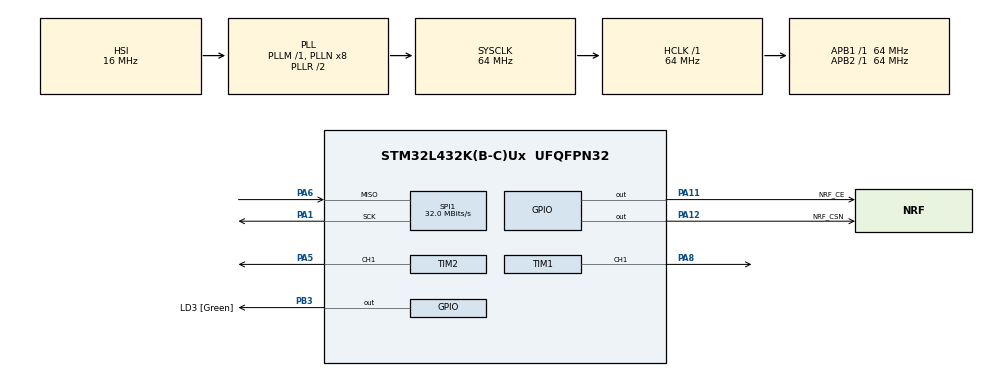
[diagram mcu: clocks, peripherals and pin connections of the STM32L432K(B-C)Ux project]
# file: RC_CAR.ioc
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FREERTOS.Tasks01=defaultTask,24,128,StartDefaultTask,Default,NULL,Dynamic,NULL,NULL
Mcu.Family=STM32L4
Mcu.Name=STM32L432K(B-C)Ux
Mcu.Package=UFQFPN32
NVIC.PriorityGroup=NVIC_PRIORITYGROUP_4
NVIC.TIM7_IRQn=true\:15\:0\:false\:false\:true\:false\:false\:true\:true
NVIC.TimeBase=TIM7_IRQn
NVIC.TimeBaseIP=TIM7
PA1.Mode=RX_Only_Simplex_Unidirect_Master
PA1.Signal=SPI1_SCK
PA11.GPIO_Label=NRF_CE
PA11.Signal=GPIO_Output
PA12.GPIO_Label=NRF_CSN
PA12.Signal=GPIO_Output
PA5.Signal=S_TIM2_CH1
PA6.Mode=RX_Only_Simplex_Unidirect_Master
PA6.Signal=SPI1_MISO
PA8.Signal=S_TIM1_CH1
PB3\ (JTDO-TRACESWO).GPIO_Label=LD3 [Green]
PB3\ (JTDO-TRACESWO).Signal=GPIO_Output
ProjectManager.HeapSize=0x200
ProjectManager.StackSize=0x400
ProjectManager.TargetToolchain=Makefile
RCC.ADCFreq_Value=64000000
RCC.AHBFreq_Value=64000000
RCC.APB1Freq_Value=64000000
RCC.APB1TimFreq_Value=64000000
RCC.APB2Freq_Value=64000000
RCC.APB2TimFreq_Value=64000000
RCC.CortexFreq_Value=64000000
RCC.HCLKFreq_Value=64000000
RCC.HSE_VALUE=8000000
RCC.HSI16_VALUE=16000000
RCC.HSI48_VALUE=48000000
RCC.HSI_VALUE=16000000
RCC.LSE_VALUE=32768
RCC.MSI_VALUE=4000000
RCC.PLLMUL=RCC_PLLMUL_4
RCC.PLLSourceVirtual=RCC_PLLSOURCE_HSI
RCC.SYSCLKFreq_VALUE=64000000
RCC.SYSCLKSource=RCC_SYSCLKSOURCE_PLLCLK
RCC.USBFreq_Value=64000000
RCC.VCOOutputFreq_Value=128000000
SH.S_TIM1_CH1.0=TIM1_CH1,PWM Generation1 CH1
SH.S_TIM2_CH1.0=TIM2_CH1,PWM Generation1 CH1
SPI1.BaudRatePrescaler=SPI_BAUDRATEPRESCALER_2
SPI1.CalculateBaudRate=32.0 MBits/s
SPI1.Direction=SPI_DIRECTION_2LINES_RXONLY
SPI1.Mode=SPI_MODE_MASTER
SPI1.VirtualType=VM_MASTER
TIM1.AutoReloadPreload=TIM_AUTORELOAD_PRELOAD_ENABLE
TIM1.Channel-PWM\ Generation1\ CH1=TIM_CHANNEL_1
TIM1.Period=3999
TIM1.Prescaler=319
TIM1.Pulse-PWM\ Generation1\ CH1=0
TIM2.AutoReloadPreload=TIM_AUTORELOAD_PRELOAD_ENABLE
TIM2.Channel-PWM\ Generation1\ CH1=TIM_CHANNEL_1
TIM2.Period=19999
TIM2.Prescaler=63
TIM2.Pulse-PWM\ Generation1\ CH1=1500
VP_FREERTOS_VS_CMSIS_V2.Mode=CMSIS_V2
VP_SYS_VS_tim7.Mode=TIM7
VP_TIM1_VS_ClockSourceINT.Mode=Internal
VP_TIM2_VS_ClockSourceINT.Mode=Internal
board=NUCLEO-L432KC

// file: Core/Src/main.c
/* USER CODE BEGIN Header */
/**
 ******************************************************************************
 * @file           : main.c
 * @brief          : Main program body
 ******************************************************************************
 * @attention
 *
 * Copyright (c) 2024 STMicroelectronics.
 * All rights reserved.
 *
 * This software is licensed under terms that can be found in the LICENSE file
 * in the root directory of this software component.
 * If no LICENSE file comes with this software, it is provided AS-IS.
 *
 ******************************************************************************
 */
/* USER CODE END Header */
#include "main.h"
#include "cmsis_os.h"

SPI_HandleTypeDef hspi1;

TIM_HandleTypeDef htim1;
TIM_HandleTypeDef htim2;

/* Definitions for defaultTask */
osThreadId_t defaultTaskHandle;
const osThreadAttr_t defaultTask_attributes = {
  .name = "defaultTask",
  .stack_size = 128 * 4,
  .priority = (osPriority_t) osPriorityNormal,
};

void SystemClock_Config(void);
static void MX_GPIO_Init(void);
static void MX_SPI1_Init(void);
static void MX_TIM1_Init(void);
static void MX_TIM2_Init(void);
void StartDefaultTask(void *argument);

int main(void)
{

  /* MCU Configuration--------------------------------------------------------*/

  /* Reset of all peripherals, Initializes the Flash interface and the Systick. */
  HAL_Init();

  /* Configure the system clock */
  SystemClock_Config();

  /* Initialize all configured peripherals */
  MX_GPIO_Init();
  MX_SPI1_Init();
  MX_TIM1_Init();
  MX_TIM2_Init();
  /* USER CODE BEGIN 2 */
  Car_Init();

  /* USER CODE END 2 */

  /* Init scheduler */
  osKernelInitialize();

  /* Create the thread(s) */
  /* creation of defaultTask */
  defaultTaskHandle = osThreadNew(StartDefaultTask, NULL, &defaultTask_attributes);

  /* Start scheduler */
  osKernelStart();

  /* We should never get here as control is now taken by the scheduler */

  /* Infinite loop */
  while (1)
  {

  }
}

void SystemClock_Config(void)
{
  RCC_OscInitTypeDef RCC_OscInitStruct = {0};
  RCC_ClkInitTypeDef RCC_ClkInitStruct = {0};

  /** Configure the main internal regulator output voltage
  */
  if (HAL_PWREx_ControlVoltageScaling(PWR_REGULATOR_VOLTAGE_SCALE1) != HAL_OK)
  {
    Error_Handler();
  }

  /** Initializes the RCC Oscillators according to the specified parameters
  * in the RCC_OscInitTypeDef structure.
  */
  RCC_OscInitStruct.OscillatorType = RCC_OSCILLATORTYPE_HSI;
  RCC_OscInitStruct.HSIState = RCC_HSI_ON;
  RCC_OscInitStruct.HSICalibrationValue = RCC_HSICALIBRATION_DEFAULT;
  RCC_OscInitStruct.PLL.PLLState = RCC_PLL_ON;
  RCC_OscInitStruct.PLL.PLLSource = RCC_PLLSOURCE_HSI;
  RCC_OscInitStruct.PLL.PLLM = 1;
  RCC_OscInitStruct.PLL.PLLN = 8;
  RCC_OscInitStruct.PLL.PLLP = RCC_PLLP_DIV7;
  RCC_OscInitStruct.PLL.PLLQ = RCC_PLLQ_DIV2;
  RCC_OscInitStruct.PLL.PLLR = RCC_PLLR_DIV2;
  if (HAL_RCC_OscConfig(&RCC_OscInitStruct) != HAL_OK)
  {
    Error_Handler();
  }

  /** Initializes the CPU, AHB and APB buses clocks
  */
  RCC_ClkInitStruct.ClockType = RCC_CLOCKTYPE_HCLK|RCC_CLOCKTYPE_SYSCLK
                              |RCC_CLOCKTYPE_PCLK1|RCC_CLOCKTYPE_PCLK2;
  RCC_ClkInitStruct.SYSCLKSource = RCC_SYSCLKSOURCE_PLLCLK;
  RCC_ClkInitStruct.AHBCLKDivider = RCC_SYSCLK_DIV1;
  RCC_ClkInitStruct.APB1CLKDivider = RCC_HCLK_DIV1;
  RCC_ClkInitStruct.APB2CLKDivider = RCC_HCLK_DIV1;

  if (HAL_RCC_ClockConfig(&RCC_ClkInitStruct, FLASH_LATENCY_3) != HAL_OK)
  {
    Error_Handler();
  }
}

static void MX_SPI1_Init(void)
{

  /* SPI1 parameter configuration*/
  hspi1.Instance = SPI1;
  hspi1.Init.Mode = SPI_MODE_MASTER;
  hspi1.Init.Direction = SPI_DIRECTION_2LINES_RXONLY;
  hspi1.Init.DataSize = SPI_DATASIZE_4BIT;
  hspi1.Init.CLKPolarity = SPI_POLARITY_LOW;
  hspi1.Init.CLKPhase = SPI_PHASE_1EDGE;
  hspi1.Init.NSS = SPI_NSS_SOFT;
  hspi1.Init.BaudRatePrescaler = SPI_BAUDRATEPRESCALER_2;
  hspi1.Init.FirstBit = SPI_FIRSTBIT_MSB;
  hspi1.Init.TIMode = SPI_TIMODE_DISABLE;
  hspi1.Init.CRCCalculation = SPI_CRCCALCULATION_DISABLE;
  hspi1.Init.CRCPolynomial = 7;
  hspi1.Init.CRCLength = SPI_CRC_LENGTH_DATASIZE;
  hspi1.Init.NSSPMode = SPI_NSS_PULSE_ENABLE;
  if (HAL_SPI_Init(&hspi1) != HAL_OK)
  {
    Error_Handler();
  }

}

static void MX_TIM1_Init(void)
{

  TIM_ClockConfigTypeDef sClockSourceConfig = {0};
  TIM_MasterConfigTypeDef sMasterConfig = {0};
  TIM_OC_InitTypeDef sConfigOC = {0};
  TIM_BreakDeadTimeConfigTypeDef sBreakDeadTimeConfig = {0};

  htim1.Instance = TIM1;
  htim1.Init.Prescaler = 319;
  htim1.Init.CounterMode = TIM_COUNTERMODE_UP;
  htim1.Init.Period = 3999;
  htim1.Init.ClockDivision = TIM_CLOCKDIVISION_DIV1;
  htim1.Init.RepetitionCounter = 0;
  htim1.Init.AutoReloadPreload = TIM_AUTORELOAD_PRELOAD_ENABLE;
  if (HAL_TIM_Base_Init(&htim1) != HAL_OK)
  {
    Error_Handler();
  }
  sClockSourceConfig.ClockSource = TIM_CLOCKSOURCE_INTERNAL;
  if (HAL_TIM_ConfigClockSource(&htim1, &sClockSourceConfig) != HAL_OK)
  {
    Error_Handler();
  }
  if (HAL_TIM_PWM_Init(&htim1) != HAL_OK)
  {
    Error_Handler();
  }
  sMasterConfig.MasterOutputTrigger = TIM_TRGO_RESET;
  sMasterConfig.MasterOutputTrigger2 = TIM_TRGO2_RESET;
  sMasterConfig.MasterSlaveMode = TIM_MASTERSLAVEMODE_DISABLE;
  if (HAL_TIMEx_MasterConfigSynchronization(&htim1, &sMasterConfig) != HAL_OK)
  {
    Error_Handler();
  }
  sConfigOC.OCMode = TIM_OCMODE_PWM1;
  sConfigOC.Pulse = 0;
  sConfigOC.OCPolarity = TIM_OCPOLARITY_HIGH;
  sConfigOC.OCNPolarity = TIM_OCNPOLARITY_HIGH;
  sConfigOC.OCFastMode = TIM_OCFAST_DISABLE;
  sConfigOC.OCIdleState = TIM_OCIDLESTATE_RESET;
  sConfigOC.OCNIdleState = TIM_OCNIDLESTATE_RESET;
  if (HAL_TIM_PWM_ConfigChannel(&htim1, &sConfigOC, TIM_CHANNEL_1) != HAL_OK)
  {
    Error_Handler();
  }
  sBreakDeadTimeConfig.OffStateRunMode = TIM_OSSR_DISABLE;
  sBreakDeadTimeConfig.OffStateIDLEMode = TIM_OSSI_DISABLE;
  sBreakDeadTimeConfig.LockLevel = TIM_LOCKLEVEL_OFF;
  sBreakDeadTimeConfig.DeadTime = 0;
  sBreakDeadTimeConfig.BreakState = TIM_BREAK_DISABLE;
  sBreakDeadTimeConfig.BreakPolarity = TIM_BREAKPOLARITY_HIGH;
  sBreakDeadTimeConfig.BreakFilter = 0;
  sBreakDeadTimeConfig.Break2State = TIM_BREAK2_DISABLE;
  sBreakDeadTimeConfig.Break2Polarity = TIM_BREAK2POLARITY_HIGH;
  sBreakDeadTimeConfig.Break2Filter = 0;
  sBreakDeadTimeConfig.AutomaticOutput = TIM_AUTOMATICOUTPUT_DISABLE;
  if (HAL_TIMEx_ConfigBreakDeadTime(&htim1, &sBreakDeadTimeConfig) != HAL_OK)
  {
    Error_Handler();
  }
  HAL_TIM_MspPostInit(&htim1);

}

static void MX_TIM2_Init(void)
{

  TIM_ClockConfigTypeDef sClockSourceConfig = {0};
  TIM_MasterConfigTypeDef sMasterConfig = {0};
  TIM_OC_InitTypeDef sConfigOC = {0};

  htim2.Instance = TIM2;
  htim2.Init.Prescaler = 63;
  htim2.Init.CounterMode = TIM_COUNTERMODE_UP;
  htim2.Init.Period = 19999;
  htim2.Init.ClockDivision = TIM_CLOCKDIVISION_DIV1;
  htim2.Init.AutoReloadPreload = TIM_AUTORELOAD_PRELOAD_ENABLE;
  if (HAL_TIM_Base_Init(&htim2) != HAL_OK)
  {
    Error_Handler();
  }
  sClockSourceConfig.ClockSource = TIM_CLOCKSOURCE_INTERNAL;
  if (HAL_TIM_ConfigClockSource(&htim2, &sClockSourceConfig) != HAL_OK)
  {
    Error_Handler();
  }
  if (HAL_TIM_PWM_Init(&htim2) != HAL_OK)
  {
    Error_Handler();
  }
  sMasterConfig.MasterOutputTrigger = TIM_TRGO_RESET;
  sMasterConfig.MasterSlaveMode = TIM_MASTERSLAVEMODE_DISABLE;
  if (HAL_TIMEx_MasterConfigSynchronization(&htim2, &sMasterConfig) != HAL_OK)
  {
    Error_Handler();
  }
  sConfigOC.OCMode = TIM_OCMODE_PWM1;
  sConfigOC.Pulse = 1500;
  sConfigOC.OCPolarity = TIM_OCPOLARITY_HIGH;
  sConfigOC.OCFastMode = TIM_OCFAST_DISABLE;
  if (HAL_TIM_PWM_ConfigChannel(&htim2, &sConfigOC, TIM_CHANNEL_1) != HAL_OK)
  {
    Error_Handler();
  }
  HAL_TIM_MspPostInit(&htim2);

}

static void MX_GPIO_Init(void)
{
  GPIO_InitTypeDef GPIO_InitStruct = {0};

  /* GPIO Ports Clock Enable */
  __HAL_RCC_GPIOA_CLK_ENABLE();
  __HAL_RCC_GPIOB_CLK_ENABLE();

  /*Configure GPIO pin Output Level */
  HAL_GPIO_WritePin(GPIOA, NRF_CE_Pin|NRF_CSN_Pin, GPIO_PIN_RESET);

  /*Configure GPIO pin Output Level */
  HAL_GPIO_WritePin(LD3_GPIO_Port, LD3_Pin, GPIO_PIN_RESET);

  /*Configure GPIO pins : NRF_CE_Pin NRF_CSN_Pin */
  GPIO_InitStruct.Pin = NRF_CE_Pin|NRF_CSN_Pin;
  GPIO_InitStruct.Mode = GPIO_MODE_OUTPUT_PP;
  GPIO_InitStruct.Pull = GPIO_NOPULL;
  GPIO_InitStruct.Speed = GPIO_SPEED_FREQ_LOW;
  HAL_GPIO_Init(GPIOA, &GPIO_InitStruct);

  /*Configure GPIO pin : LD3_Pin */
  GPIO_InitStruct.Pin = LD3_Pin;
  GPIO_InitStruct.Mode = GPIO_MODE_OUTPUT_PP;
  GPIO_InitStruct.Pull = GPIO_NOPULL;
  GPIO_InitStruct.Speed = GPIO_SPEED_FREQ_LOW;
  HAL_GPIO_Init(LD3_GPIO_Port, &GPIO_InitStruct);

}

void StartDefaultTask(void *argument)
{
  for (;;)
  {
    osDelay(1);
  }
}

void HAL_TIM_PeriodElapsedCallback(TIM_HandleTypeDef *htim)
{
  if (htim->Instance == TIM7) {
    HAL_IncTick();
  }
}

void Error_Handler(void)
{
  __disable_irq();
  while (1)
  {
  }
}
